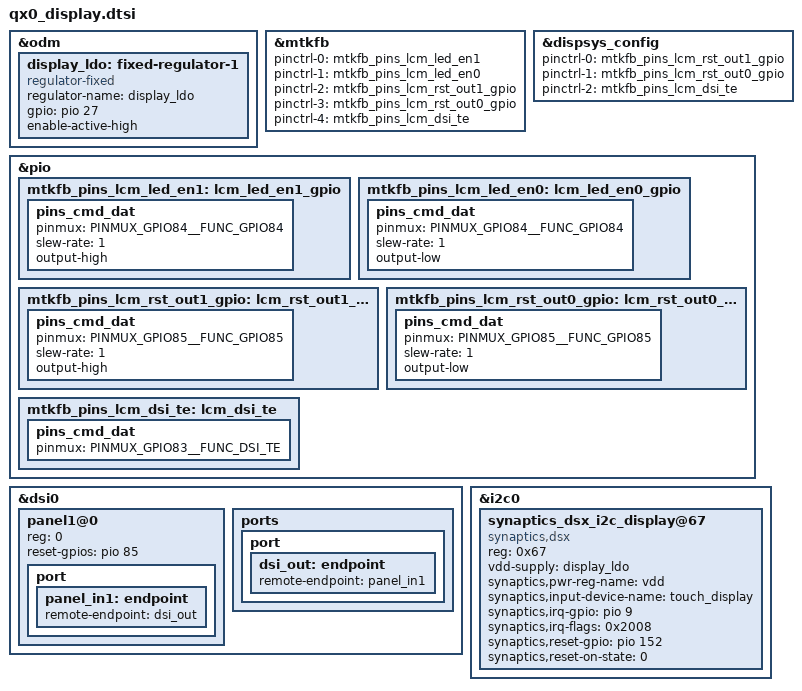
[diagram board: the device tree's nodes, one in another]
&odm {
	display_ldo: fixed-regulator-1 {
		compatible = "regulator-fixed";
		regulator-name = "display_ldo";
		gpio = <&pio 27 0>;
		enable-active-high;
	};
};

&mtkfb {
	pinctrl-names = "lcm_led_en1_gpio", "lcm_led_en0_gpio",
		"lcm_rst_out1_gpio", "lcm_rst_out0_gpio",
		"mode_te_te";
	pinctrl-0 = <&mtkfb_pins_lcm_led_en1>;
	pinctrl-1 = <&mtkfb_pins_lcm_led_en0>;
	pinctrl-2 = <&mtkfb_pins_lcm_rst_out1_gpio>;
	pinctrl-3 = <&mtkfb_pins_lcm_rst_out0_gpio>;
	pinctrl-4 = <&mtkfb_pins_lcm_dsi_te>;
	status = "okay";
};

&dispsys_config {
	pinctrl-names =
		"lcm_rst_out1_gpio", "lcm_rst_out0_gpio",
		"mode_te_te";
	pinctrl-0 = <&mtkfb_pins_lcm_rst_out1_gpio>;
	pinctrl-1 = <&mtkfb_pins_lcm_rst_out0_gpio>;
	pinctrl-2 = <&mtkfb_pins_lcm_dsi_te>;
	status = "okay";
};

&pio {
	mtkfb_pins_lcm_led_en1: lcm_led_en1_gpio {
		pins_cmd_dat {
			pinmux = <PINMUX_GPIO84__FUNC_GPIO84>;
			slew-rate = <1>;
			output-high;
		};
	};

	mtkfb_pins_lcm_led_en0: lcm_led_en0_gpio {
		pins_cmd_dat {
			pinmux = <PINMUX_GPIO84__FUNC_GPIO84>;
			slew-rate = <1>;
			output-low;
		};
	};

	mtkfb_pins_lcm_rst_out1_gpio: lcm_rst_out1_gpio {
		pins_cmd_dat {
			pinmux = <PINMUX_GPIO85__FUNC_GPIO85>;
			slew-rate = <1>;
			output-high;
		};
	};

	mtkfb_pins_lcm_rst_out0_gpio: lcm_rst_out0_gpio {
		pins_cmd_dat {
			pinmux = <PINMUX_GPIO85__FUNC_GPIO85>;
			slew-rate = <1>;
			output-low;
		};
	};
	mtkfb_pins_lcm_dsi_te: lcm_dsi_te {
		pins_cmd_dat {
			pinmux = <PINMUX_GPIO83__FUNC_DSI_TE>;
		};
	};
};

&dsi0 {
	status = "okay";
	#address-cells = <1>;
	#size-cells = <0>;

	panel1@0 {
		reg = <0>;
		reset-gpios = <&pio 85 0>;
		port {
			panel_in1: endpoint {
				remote-endpoint = <&dsi_out>;
			};
		};
	};

	ports {
		port {
			dsi_out: endpoint {
				remote-endpoint = <&panel_in1>;
			};
		};
	};
};

&i2c0 {
	synaptics_dsx_i2c_display@67 {
		compatible = "synaptics,dsx";
		reg = <0x67>;
		vdd-supply = <&display_ldo>;
		synaptics,pwr-reg-name = "vdd";
		synaptics,input-device-name = "touch_display";
		synaptics,irq-gpio = <&pio 9 0>;
		synaptics,irq-flags = <0x2008>;
		synaptics,reset-gpio = <&pio 152 0>;
		synaptics,reset-on-state = <0>;
	};
};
